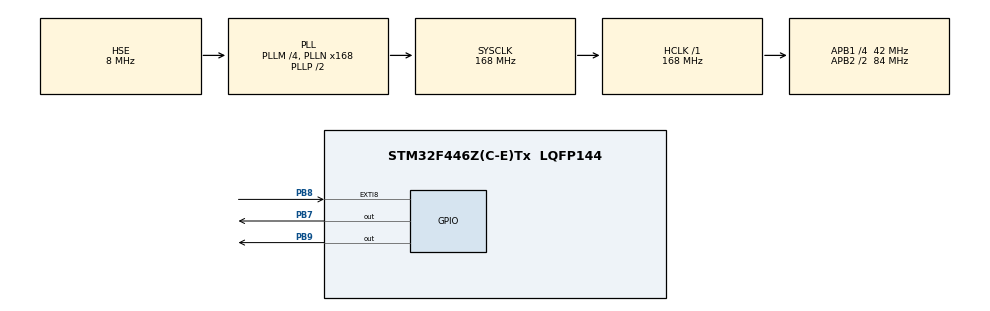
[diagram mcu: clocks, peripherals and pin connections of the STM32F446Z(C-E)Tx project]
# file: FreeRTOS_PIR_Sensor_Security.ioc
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FREERTOS.Tasks01=defaultTask,24,128,StartDefaultTask,Default,NULL,Dynamic,NULL,NULL
FREERTOS.configUSE_NEWLIB_REENTRANT=1
Mcu.Family=STM32F4
Mcu.Name=STM32F446Z(C-E)Tx
Mcu.Package=LQFP144
NVIC.EXTI9_5_IRQn=true\:5\:0\:false\:false\:true\:true\:true\:true\:true
NVIC.PriorityGroup=NVIC_PRIORITYGROUP_4
NVIC.TIM7_IRQn=true\:15\:0\:false\:false\:true\:false\:false\:true\:true
NVIC.TimeBase=TIM7_IRQn
NVIC.TimeBaseIP=TIM7
PB7.Signal=GPIO_Output
PB8.GPIO_ModeDefaultEXTI=GPIO_MODE_IT_RISING_FALLING
PB8.Signal=GPXTI8
PB9.Signal=GPIO_Output
PH0-OSC_IN.Mode=HSE-External-Oscillator
PH0-OSC_IN.Signal=RCC_OSC_IN
PH1-OSC_OUT.Mode=HSE-External-Oscillator
PH1-OSC_OUT.Signal=RCC_OSC_OUT
ProjectManager.HeapSize=0x200
ProjectManager.StackSize=0x400
ProjectManager.TargetToolchain=STM32CubeIDE
RCC.AHBFreq_Value=168000000
RCC.APB1CLKDivider=RCC_HCLK_DIV4
RCC.APB1Freq_Value=42000000
RCC.APB1TimFreq_Value=84000000
RCC.APB2CLKDivider=RCC_HCLK_DIV2
RCC.APB2Freq_Value=84000000
RCC.APB2TimFreq_Value=168000000
RCC.CortexFreq_Value=168000000
RCC.HCLKFreq_Value=168000000
RCC.HSE_VALUE=8000000
RCC.PLLM=4
RCC.PLLN=168
RCC.PLLSourceVirtual=RCC_PLLSOURCE_HSE
RCC.SYSCLKFreq_VALUE=168000000
RCC.SYSCLKSource=RCC_SYSCLKSOURCE_PLLCLK
RCC.USBFreq_Value=168000000
RCC.VCOOutputFreq_Value=336000000
VP_FREERTOS_VS_CMSIS_V2.Mode=CMSIS_V2
VP_SYS_VS_tim7.Mode=TIM7
board=custom

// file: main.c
/* USER CODE BEGIN Header */
/**
  ******************************************************************************
  * @file           : main.c
  * @brief          : Main program body
  ******************************************************************************
  * @attention
  *
  * Copyright (c) 2025 STMicroelectronics.
  * All rights reserved.
  *
  * This software is licensed under terms that can be found in the LICENSE file
  * in the root directory of this software component.
  * If no LICENSE file comes with this software, it is provided AS-IS.
  *
  ******************************************************************************
  */
/* USER CODE END Header */
#include "main.h"
#include "cmsis_os.h"

/* USER CODE BEGIN Includes */
#include "FreeRTOS.h"
#include "task.h"
#include "semphr.h"

/* USER CODE END Includes */

/* Definitions for defaultTask */
/*osThreadId_t defaultTaskHandle;
const osThreadAttr_t defaultTask_attributes = {
  .name = "defaultTask",
  .stack_size = 128 * 4,
  .priority = (osPriority_t) osPriorityNormal,
};*/
/* USER CODE BEGIN PV */
BaseType_t xHigherPriorityTaskWoken;
SemaphoreHandle_t xBinarySemaphore;
BaseType_t status;
/* USER CODE END PV */

void SystemClock_Config(void);
static void MX_GPIO_Init(void);
void StartDefaultTask(void *argument);

/* USER CODE BEGIN 0 */

void vPIRtask(void * pvParameters){

	for(;;){

		status = xSemaphoreTake(xBinarySemaphore, portMAX_DELAY);
		if(status == pdTRUE){

			HAL_GPIO_WritePin(GPIOB, GPIO_PIN_7|GPIO_PIN_9, GPIO_PIN_SET);
			vTaskDelay(pdMS_TO_TICKS(1000));
			HAL_GPIO_WritePin(GPIOB, GPIO_PIN_7|GPIO_PIN_9, GPIO_PIN_RESET);

		}

	}
}

/* USER CODE END 0 */

int main(void)
{

  /* MCU Configuration--------------------------------------------------------*/

  /* Reset of all peripherals, Initializes the Flash interface and the Systick. */
  HAL_Init();

  /* Configure the system clock */
  SystemClock_Config();

  /* Initialize all configured peripherals */
  MX_GPIO_Init();
  /* USER CODE BEGIN 2 */

  xBinarySemaphore = xSemaphoreCreateBinary();
      if (xBinarySemaphore == NULL) {

          for(;;);
      }

  xTaskCreate(vPIRtask, "PIR", 1000, NULL, 1, NULL);
  vTaskStartScheduler();
  for(;;);

  /* USER CODE END 2 */

  /* Init scheduler */
  //osKernelInitialize();

  /* Create the thread(s) */
  /* creation of defaultTask */
  //defaultTaskHandle = osThreadNew(StartDefaultTask, NULL, &defaultTask_attributes);

  /* Start scheduler */
  //osKernelStart();

  /* We should never get here as control is now taken by the scheduler */

  /* Infinite loop */
  while (1)
  {

  }
}

void SystemClock_Config(void)
{
  RCC_OscInitTypeDef RCC_OscInitStruct = {0};
  RCC_ClkInitTypeDef RCC_ClkInitStruct = {0};

  /** Configure the main internal regulator output voltage
  */
  __HAL_RCC_PWR_CLK_ENABLE();
  __HAL_PWR_VOLTAGESCALING_CONFIG(PWR_REGULATOR_VOLTAGE_SCALE1);

  /** Initializes the RCC Oscillators according to the specified parameters
  * in the RCC_OscInitTypeDef structure.
  */
  RCC_OscInitStruct.OscillatorType = RCC_OSCILLATORTYPE_HSE;
  RCC_OscInitStruct.HSEState = RCC_HSE_ON;
  RCC_OscInitStruct.PLL.PLLState = RCC_PLL_ON;
  RCC_OscInitStruct.PLL.PLLSource = RCC_PLLSOURCE_HSE;
  RCC_OscInitStruct.PLL.PLLM = 4;
  RCC_OscInitStruct.PLL.PLLN = 168;
  RCC_OscInitStruct.PLL.PLLP = RCC_PLLP_DIV2;
  RCC_OscInitStruct.PLL.PLLQ = 2;
  RCC_OscInitStruct.PLL.PLLR = 2;
  if (HAL_RCC_OscConfig(&RCC_OscInitStruct) != HAL_OK)
  {
    Error_Handler();
  }

  /** Initializes the CPU, AHB and APB buses clocks
  */
  RCC_ClkInitStruct.ClockType = RCC_CLOCKTYPE_HCLK|RCC_CLOCKTYPE_SYSCLK
                              |RCC_CLOCKTYPE_PCLK1|RCC_CLOCKTYPE_PCLK2;
  RCC_ClkInitStruct.SYSCLKSource = RCC_SYSCLKSOURCE_PLLCLK;
  RCC_ClkInitStruct.AHBCLKDivider = RCC_SYSCLK_DIV1;
  RCC_ClkInitStruct.APB1CLKDivider = RCC_HCLK_DIV4;
  RCC_ClkInitStruct.APB2CLKDivider = RCC_HCLK_DIV2;

  if (HAL_RCC_ClockConfig(&RCC_ClkInitStruct, FLASH_LATENCY_5) != HAL_OK)
  {
    Error_Handler();
  }
}

static void MX_GPIO_Init(void)
{
  GPIO_InitTypeDef GPIO_InitStruct = {0};

  /* GPIO Ports Clock Enable */
  __HAL_RCC_GPIOH_CLK_ENABLE();
  __HAL_RCC_GPIOB_CLK_ENABLE();

  /*Configure GPIO pin Output Level */
  HAL_GPIO_WritePin(GPIOB, GPIO_PIN_7|GPIO_PIN_9, GPIO_PIN_RESET);

  /*Configure GPIO pins : PB7 PB9 */
  GPIO_InitStruct.Pin = GPIO_PIN_7|GPIO_PIN_9;
  GPIO_InitStruct.Mode = GPIO_MODE_OUTPUT_PP;
  GPIO_InitStruct.Pull = GPIO_NOPULL;
  GPIO_InitStruct.Speed = GPIO_SPEED_FREQ_LOW;
  HAL_GPIO_Init(GPIOB, &GPIO_InitStruct);

  /*Configure GPIO pin : PB8 */
  GPIO_InitStruct.Pin = GPIO_PIN_8;
  GPIO_InitStruct.Mode = GPIO_MODE_IT_RISING_FALLING;
  GPIO_InitStruct.Pull = GPIO_NOPULL;
  HAL_GPIO_Init(GPIOB, &GPIO_InitStruct);

  /* EXTI interrupt init*/
  HAL_NVIC_SetPriority(EXTI9_5_IRQn, 5, 0);
  HAL_NVIC_EnableIRQ(EXTI9_5_IRQn);

}

void StartDefaultTask(void *argument)
{
  for(;;)
  {
    osDelay(1);
  }
}

void HAL_TIM_PeriodElapsedCallback(TIM_HandleTypeDef *htim)
{
  if (htim->Instance == TIM7)
  {
    HAL_IncTick();
  }
}

void Error_Handler(void)
{
  __disable_irq();
  while (1)
  {
  }
}
